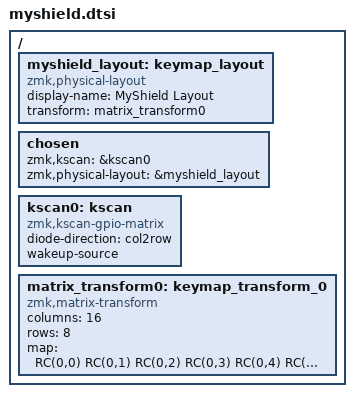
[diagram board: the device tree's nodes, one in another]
#include <dt-bindings/zmk/matrix_transform.h>
#include "myshield-layouts.dtsi"
/ {
    myshield_layout: keymap_layout {
        compatible = "zmk,physical-layout";
        display-name = "MyShield Layout";
        transform = <&matrix_transform0>; // <--- add this line
    };

    chosen {
        zmk,kscan = &kscan0;
        zmk,physical-layout = &myshield_layout;
    };

    kscan0: kscan {
        compatible = "zmk,kscan-gpio-matrix";
        diode-direction = "col2row";
        wakeup-source;
        
        // This node is intentionally left empty.
        // It will be populated by your myshield_left.overlay 
        // and myshield_right.overlay files.
    };

    matrix_transform0: keymap_transform_0 {
        compatible = "zmk,matrix-transform";
        columns = <16>; // 8 cols left + 8 cols right
        rows = <8>;     // 8 rows (from your overlay)

        // 56 logical keys (4x7 per side)
        map = <
        // Left Hand (Cols 0-7)                                            // Right Hand (Cols 8-15)
        RC(0,0) RC(0,1) RC(0,2) RC(0,3) RC(0,4) RC(0,5) RC(0,6) RC(0xFFFF,0xFFFF)   RC(0,8) RC(0,9) RC(0,10) RC(0,11) RC(0,12) RC(0,13) RC(0,14) RC(0xFFFF,0xFFFF)
        RC(1,0) RC(1,1) RC(1,2) RC(1,3) RC(1,4) RC(1,5) RC(1,6) RC(0xFFFF,0xFFFF)   RC(1,8) RC(1,9) RC(1,10) RC(1,11) RC(1,12) RC(1,13) RC(1,14) RC(0xFFFF,0xFFFF)
        RC(2,0) RC(2,1) RC(2,2) RC(2,3) RC(2,4) RC(2,5) RC(2,6) RC(0xFFFF,0xFFFF)   RC(2,8) RC(2,9) RC(2,10) RC(2,11) RC(2,12) RC(2,13) RC(2,14) RC(0xFFFF,0xFFFF)
        RC(3,0) RC(3,1) RC(3,2) RC(3,3) RC(3,4) RC(3,5) RC(3,6) RC(0xFFFF,0xFFFF)   RC(3,8) RC(3,9) RC(3,10) RC(3,11) RC(3,12) RC(3,13) RC(3,14) RC(0xFFFF,0xFFFF)
        
        // These 4 rows are unused in this logical layout, but your 
        // 8-row overlay requires them to be defined.
        // If your keys are on these rows, move RC() entries down here.
        RC(0xFFFF,0xFFFF) RC(0xFFFF,0xFFFF) RC(0xFFFF,0xFFFF) RC(0xFFFF,0xFFFF) RC(0xFFFF,0xFFFF) RC(0xFFFF,0xFFFF) RC(0xFFFF,0xFFFF) RC(0xFFFF,0xFFFF)   RC(0xFFFF,0xFFFF) RC(0xFFFF,0xFFFF) RC(0xFFFF,0xFFFF) RC(0xFFFF,0xFFFF) RC(0xFFFF,0xFFFF) RC(0xFFFF,0xFFFF) RC(0xFFFF,0xFFFF) RC(0xFFFF,0xFFFF)
        RC(0xFFFF,0xFFFF) RC(0xFFFF,0xFFFF) RC(0xFFFF,0xFFFF) RC(0xFFFF,0xFFFF) RC(0xFFFF,0xFFFF) RC(0xFFFF,0xFFFF) RC(0xFFFF,0xFFFF) RC(0xFFFF,0xFFFF)   RC(0xFFFF,0xFFFF) RC(0xFFFF,0xFFFF) RC(0xFFFF,0xFFFF) RC(0xFFFF,0xFFFF) RC(0xFFFF,0xFFFF) RC(0xFFFF,0xFFFF) RC(0xFFFF,0xFFFF) RC(0xFFFF,0xFFFF)
        RC(0xFFFF,0xFFFF) RC(0xFFFF,0xFFFF) RC(0xFFFF,0xFFFF) RC(0xFFFF,0xFFFF) RC(0xFFFF,0xFFFF) RC(0xFFFF,0xFFFF) RC(0xFFFF,0xFFFF) RC(0xFFFF,0xFFFF)   RC(0xFFFF,0xFFFF) RC(0xFFFF,0xFFFF) RC(0xFFFF,0xFFFF) RC(0xFFFF,0xFFFF) RC(0xFFFF,0xFFFF) RC(0xFFFF,0xFFFF) RC(0xFFFF,0xFFFF) RC(0xFFFF,0xFFFF)
        RC(0xFFFF,0xFFFF) RC(0xFFFF,0xFFFF) RC(0xFFFF,0xFFFF) RC(0xFFFF,0xFFFF) RC(0xFFFF,0xFFFF) RC(0xFFFF,0xFFFF) RC(0xFFFF,0xFFFF) RC(0xFFFF,0xFFFF)   RC(0xFFFF,0xFFFF) RC(0xFFFF,0xFFFF) RC(0xFFFF,0xFFFF) RC(0xFFFF,0xFFFF) RC(0xFFFF,0xFFFF) RC(0xFFFF,0xFFFF) RC(0xFFFF,0xFFFF) RC(0xFFFF,0xFFFF)
        >;
    };
};


